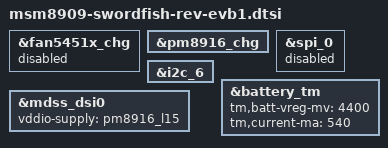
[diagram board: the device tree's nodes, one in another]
/* Copyright (c) 2016, LGE Inc. All rights reserved.
 *
 * This program is free software; you can redistribute it and/or modify
 * it under the terms of the GNU General Public License version 2 and
 * only version 2 as published by the Free Software Foundation.
 *
 * This program is distributed in the hope that it will be useful,
 * but WITHOUT ANY WARRANTY; without even the implied warranty of
 * MERCHANTABILITY or FITNESS FOR A PARTICULAR PURPOSE.  See the
 * GNU General Public License for more details.
 */

#include "msm8909-swordfish.dtsi"
#include "../qcom/msm8909w-gpu.dtsi"
#include "../qcom/msm8909-pm8916.dtsi"
#include "../qcom/msm8909w.dtsi"
#include "msm8909-swordfish-panel.dtsi"
#include "msm8909-pm8916-swordfish.dtsi"
#include "msm8909-swordfish-sound.dtsi"

&fan5451x_chg {
	status = "disabled";
};

&pm8916_chg {
	status = "ok";
};

&spi_0 {
	status = "disabled";
};

&i2c_6 {
	status = "ok";
};

&battery_tm {
	tm,batt-vreg-mv = <4400>;
	tm,current-ma = <540>;
	/delete-property/ tm,wlc-config-use;
};

&mdss_dsi0 {
	vddio-supply = <&pm8916_l15>;
};
